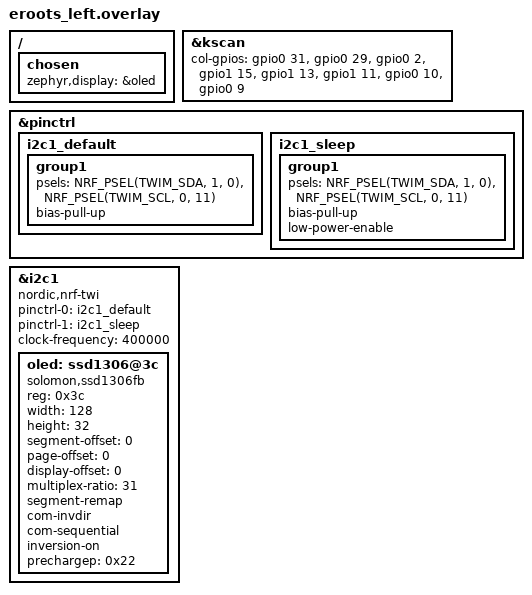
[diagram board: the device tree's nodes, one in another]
#include "eroots.dtsi"

&kscan {
    col-gpios = <&gpio0 31 GPIO_ACTIVE_HIGH>,
                <&gpio0 29 GPIO_ACTIVE_HIGH>,
                <&gpio0  2 GPIO_ACTIVE_HIGH>,
                <&gpio1 15 GPIO_ACTIVE_HIGH>,
                <&gpio1 13 GPIO_ACTIVE_HIGH>,
                <&gpio1 11 GPIO_ACTIVE_HIGH>,
                <&gpio0 10 GPIO_ACTIVE_HIGH>,
                <&gpio0  9 GPIO_ACTIVE_HIGH>;
};



&pinctrl {
    i2c1_default: i2c1_default {
		group1 {
			psels = <NRF_PSEL(TWIM_SDA, 1, 0)>,
					<NRF_PSEL(TWIM_SCL, 0, 11)>;
            bias-pull-up;
		};
	};

	i2c1_sleep: i2c1_sleep {
		group1 {
			psels = <NRF_PSEL(TWIM_SDA, 1, 0)>,
					<NRF_PSEL(TWIM_SCL, 0, 11)>;
            bias-pull-up;
			low-power-enable;
		};
	};
};

/ {
    chosen {
        zephyr,display = &oled;
    };
};

&i2c1 {
	status = "okay";

	compatible = "nordic,nrf-twi";
    pinctrl-0 = <&i2c1_default>;
	pinctrl-1 = <&i2c1_sleep>;
	pinctrl-names = "default", "sleep";
    clock-frequency = <400000>;

    oled: ssd1306@3c {
        compatible = "solomon,ssd1306fb";
        reg = <0x3c>;
        width = <128>;
        height = <32>;
        segment-offset = <0>;
        page-offset = <0>;
        display-offset = <0>;
        multiplex-ratio = <31>;
        segment-remap;
        com-invdir;
        com-sequential;
        inversion-on;
        prechargep = <0x22>;
    };
};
